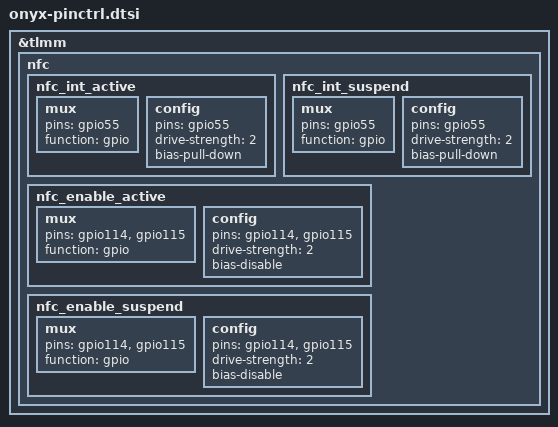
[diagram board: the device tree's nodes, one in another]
/*for onyx pinctrl */
&tlmm {
	nfc {
		nfc_int_active: nfc_int_active {
			/* active state */
			mux {
				/* NFC Read Interrupt */
				pins = "gpio55";
				function = "gpio";
			};

			config {
				pins = "gpio55";
				drive-strength = <2>; /* 2 MA */
				bias-pull-down;
			};
		};

		nfc_int_suspend: nfc_int_suspend {
			/* sleep state */
			mux {
				/* NFC Read Interrupt */
				pins = "gpio55";
				function = "gpio";
			};

			config {
				pins = "gpio55";
				drive-strength = <2>; /* 2 MA */
				bias-pull-down;
			};
		};

		nfc_enable_active: nfc_enable_active {
			mux {
				/* Enable and Clock request gpios */
				pins = "gpio114", "gpio115";
				function = "gpio";
			};

			config {
				pins = "gpio114", "gpio115";
				drive-strength = <2>; /* 2 MA */
				bias-disable;
			};
		};

		nfc_enable_suspend: nfc_enable_suspend {
			mux {
				pins = "gpio114", "gpio115";
				function = "gpio";
			};

			config {
				pins = "gpio114", "gpio115";
				drive-strength = <2>; /* 2 MA */
				bias-disable;
			};
		};
	}; //nfc
}; //tlmm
